# LPC408x_7x register map
File version: 0.7
CPU: CM4 r0p0, little endian, no MPU, no FPU, 3 interrupt priority bits
Registers are 32-bit, read-write, reset 0x0 unless marked. A register's access mark holds for its fields unless they carry their own. Offsets are from the block's base; [hi:lo] are bit positions; {n}, {i} and the like mark numbered series; 'fields as' and 'values as' point back to an identical list.

## EMC — External Memory Controller (EMC)
Base 0x2009C000
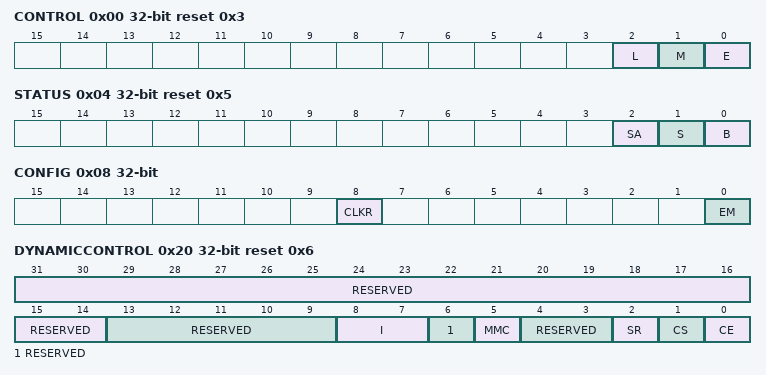
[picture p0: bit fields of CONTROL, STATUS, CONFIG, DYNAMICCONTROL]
0x00 CONTROL reset 0x3 — Controls operation of the memory controller.
  [2] L — Low-power mode. Indicates normal, or low-power mode:
    0=WARMRESET (Normal mode (warm reset value).); 1=LOWPOWER (Low-power mode. Entering low-power mode reduces memory controller power consumption. Dynamic memory is refreshed as necessary. The memory controller returns to normal functional mode by clearing the low-power mode bit (L), or by POR. This bit must only be modified when the EMC is in idle state.[1])
  [1] M — Address mirror. Indicates normal or reset memory map:
    0=NORMAL (Normal memory map.); 1=RESET (Reset memory map. Static memory EMC_CS1 is mirrored onto EMC_CS0 and EMC_DYCS0 (POR reset value).)
  [0] E — EMC Enable. Indicates if the EMC is enabled or disabled:
    0=DISABLED; 1=ENABLED (Enabled (POR and warm reset value).)
0x04 STATUS ro reset 0x5 — Provides EMC status information.
  [2] SA — Self-refresh acknowledge. This bit indicates the operating mode of the EMC.
    0=NORMAL (Normal mode); 1=SELFREFRESH (Self-refresh mode (POR reset value).)
  [1] S — Write buffer status.This bit enables the EMC to enter low-power mode or disabled mode cleanly.
    0=EMPTY (Write buffers empty (POR reset value)); 1=DATA (Write buffers contain data.)
  [0] B — Busy. This bit is used to ensure that the memory controller enters the low-power or disabled mode cleanly by determining if the memory controller is busy or not.
    0=IDLE (EMC is idle (warm reset value).); 1=BUSY (EMC is busy performing memory transactions, commands, auto-refresh cycles, or is in self-refresh mode (POR reset value).)
0x08 CONFIG — Configures operation of the memory controller
  [8] CLKR — CCLK: CLKOUT ratio. This bit must contain 0 for proper operation of the EMC.
    0=PORRESET (1:1(POR reset value)); 1=DONOTUSE (1:2 (this option is not available on the LPC178x/177x))
  [0] EM — Endian mode. On power-on reset, the value of the endian bit is 0. All data must be flushed in the EMC before switching between little-endian and big-endian modes.
    0=LITTLEENDIAN (Little-endian mode (POR reset value).); 1=BIGENDIAN (Big-endian mode.)
0x20 DYNAMICCONTROL reset 0x6 — Controls dynamic memory operation.
  [31:14] RESERVED — Reserved, user software should not write ones to reserved bits. The value read from a reserved bit is not defined.
  [13:9] RESERVED — Reserved, user software should not write ones to reserved bits. The value read from a reserved bit is not defined.
  [8:7] I — SDRAM initialization.
    0=NORMAL (Issue SDRAM NORMAL operation command (POR reset value).); 1=MODE (Issue SDRAM MODE command.); 2=PALL (Issue SDRAM PALL (precharge all) command.); 3=NOP (Issue SDRAM NOP (no operation) command))
  [6] RESERVED — Reserved, user software should not write ones to reserved bits. The value read from a reserved bit is not defined.
  [5] MMC — Memory clock control.
    0=CLKOUT_ENABLED_POR_ (CLKOUT enabled (POR reset value).); 1=CLKOUT_DISABLED (CLKOUT disabled.[3])
  [4:3] RESERVED — Reserved, user software should not write ones to reserved bits. The value read from a reserved bit is not defined.
  [2] SR — Self-refresh request, EMCSREFREQ. By writing 1 to this bit self-refresh can be entered under software control. Writing 0 to this bit returns the EMC to normal mode. The self-refresh acknowledge bit in the Status register must be polled to discover the current operating mode of the EMC.[2]
    0=NORMAL_MODE_; 1=ENTER_SELF_REFRESH_M (Enter self-refresh mode (POR reset value).)
  [1] CS — Dynamic memory clock control. When clock control is LOW the output clock CLKOUT is stopped when there are no SDRAM transactions. The clock is also stopped during self-refresh mode.
    0=STOP (CLKOUT stops when all SDRAMs are idle and during self-refresh mode.); 1=RUN (CLKOUT runs continuously (POR reset value).)
  [0] CE — Dynamic memory clock enable.
    0=POWERSAVE (Clock enable of idle devices are deasserted to save power (POR reset value).); 1=HIGH (All clock enables are driven HIGH continuously.[1])
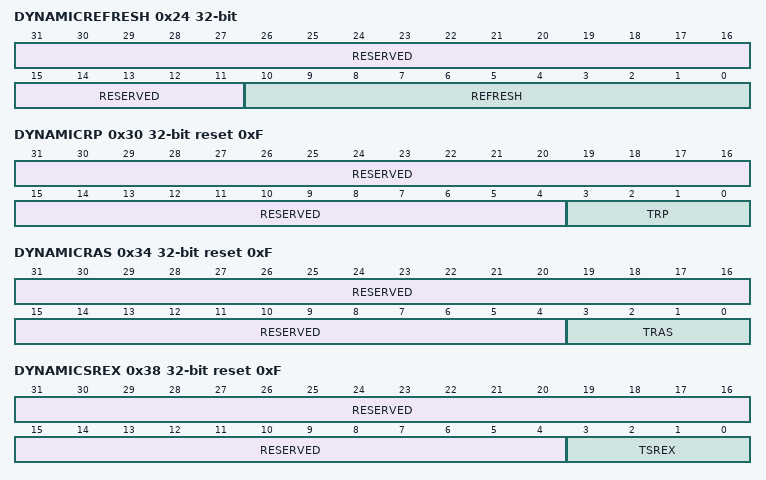
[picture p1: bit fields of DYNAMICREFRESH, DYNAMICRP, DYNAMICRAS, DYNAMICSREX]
0x24 DYNAMICREFRESH — Configures dynamic memory refresh.
  [31:11] RESERVED — Reserved, user software should not write ones to reserved bits. The value read from a reserved bit is not defined.
  [10:0] REFRESH — Refresh timer. Indicates the multiple of 16 CCLKs between SDRAM refresh cycles. 0x0 = Refresh disabled (POR reset value). 0x1 - 0x7FF = n x16 = 16n CCLKs between SDRAM refresh cycles. For example: 0x1 = 1 x 16 = 16 CCLKs between SDRAM refresh cycles. 0x8 = 8 x 16 = 128 CCLKs between SDRAM refresh cycles
0x28 DYNAMICREADCONFIG — Configures dynamic memory read strategy.
  [1:0] RD — Read data strategy
    0=CLOCK_OUT_DELAYED_ST (Clock out delayed strategy, using CLKOUT (command not delayed, clock out delayed). POR reset value.); 1=COMMAND_DELAYED_STRA (Command delayed strategy, using EMCCLKDELAY (command delayed, clock out not delayed).); 2=COMMAND_DELAYED_STRA (Command delayed strategy plus one clock cycle, using EMCCLKDELAY (command delayed, clock out not delayed).); 3=COMMAND_DELAYED_STRA (Command delayed strategy plus two clock cycles, using EMCCLKDELAY (command delayed, clock out not delayed).)
0x30 DYNAMICRP reset 0xF — Precharge command period.
  [31:4] RESERVED — Reserved, user software should not write ones to reserved bits. The value read from a reserved bit is not defined.
  [3:0] TRP — Precharge command period. 0x0 - 0xE = n + 1 clock cycles. The delay is in CCLK cycles. 0xF = 16 clock cycles (POR reset value).
0x34 DYNAMICRAS reset 0xF — Active to precharge command period.
  [31:4] RESERVED — Reserved, user software should not write ones to reserved bits. The value read from a reserved bit is not defined.
  [3:0] TRAS — Active to precharge command period. 0x0 - 0xE = n + 1 clock cycles. The delay is in CCLK cycles. 0xF = 16 clock cycles (POR reset value).
0x38 DYNAMICSREX reset 0xF — Self-refresh exit time.
  [31:4] RESERVED — Reserved, user software should not write ones to reserved bits. The value read from a reserved bit is not defined.
  [3:0] TSREX — Self-refresh exit time. 0x0 - 0xE = n + 1 clock cycles. The delay is in CCLK cycles. 0xF = 16 clock cycles (POR reset value).
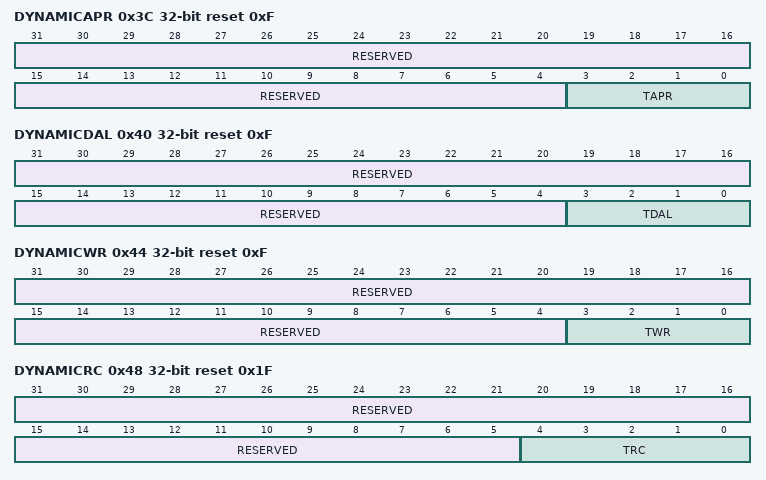
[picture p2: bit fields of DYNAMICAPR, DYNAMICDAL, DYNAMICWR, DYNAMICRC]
0x3C DYNAMICAPR reset 0xF — Last-data-out to active command time.
  [31:4] RESERVED — Reserved, user software should not write ones to reserved bits. The value read from a reserved bit is not defined.
  [3:0] TAPR — Last-data-out to active command time. 0x0 - 0xE = n + 1 clock cycles. The delay is in CCLK cycles. 0xF = 16 clock cycles (POR reset value).
0x40 DYNAMICDAL reset 0xF — Data-in to active command time.
  [31:4] RESERVED — Reserved, user software should not write ones to reserved bits. The value read from a reserved bit is not defined.
  [3:0] TDAL — Data-in to active command. 0x0 - 0xE = n clock cycles. The delay is in CCLK cycles. 0xF = 15 clock cycles (POR reset value).
0x44 DYNAMICWR reset 0xF — Write recovery time.
  [31:4] RESERVED — Reserved, user software should not write ones to reserved bits. The value read from a reserved bit is not defined.
  [3:0] TWR — Write recovery time. 0x0 - 0xE = n + 1 clock cycles. The delay is in CCLK cycles. 0xF = 16 clock cycles (POR reset value).
0x48 DYNAMICRC reset 0x1F — Selects the active to active command period.
  [31:5] RESERVED — Reserved, user software should not write ones to reserved bits. The value read from a reserved bit is not defined.
  [4:0] TRC — Active to active command period. 0x0 - 0x1E = n + 1 clock cycles. The delay is in CCLK cycles. 0x1F = 32 clock cycles (POR reset value).
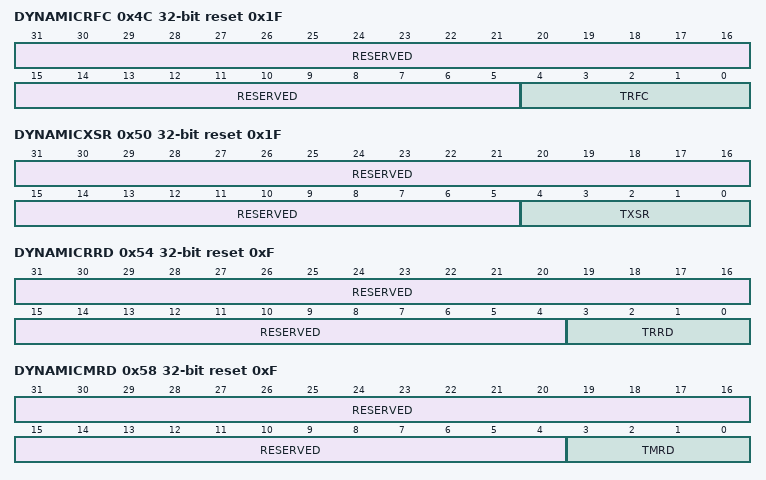
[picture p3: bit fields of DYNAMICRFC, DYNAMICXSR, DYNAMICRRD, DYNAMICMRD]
0x4C DYNAMICRFC reset 0x1F — Selects the auto-refresh period.
  [31:5] RESERVED — Reserved, user software should not write ones to reserved bits. The value read from a reserved bit is not defined.
  [4:0] TRFC — Auto-refresh period and auto-refresh to active command period. 0x0 - 0x1E = n + 1 clock cycles. The delay is in CCLK cycles. 0x1F = 32 clock cycles (POR reset value).
0x50 DYNAMICXSR reset 0x1F — Time for exit self-refresh to active command.
  [31:5] RESERVED — Reserved, user software should not write ones to reserved bits. The value read from a reserved bit is not defined.
  [4:0] TXSR — Exit self-refresh to active command time. 0x0 - 0x1E = n + 1 clock cycles. The delay is in CCLK cycles. 0x1F = 32 clock cycles (POR reset value).
0x54 DYNAMICRRD reset 0xF — Latency for active bank A to active bank B.
  [31:4] RESERVED — Reserved, user software should not write ones to reserved bits. The value read from a reserved bit is not defined.
  [3:0] TRRD — Active bank A to active bank B latency 0x0 - 0xE = n + 1 clock cycles. The delay is in CCLK cycles. 0xF = 16 clock cycles (POR reset value).
0x58 DYNAMICMRD reset 0xF — Time for load mode register to active command.
  [31:4] RESERVED — Reserved, user software should not write ones to reserved bits. The value read from a reserved bit is not defined.
  [3:0] TMRD — Load mode register to active command time. 0x0 - 0xE = n + 1 clock cycles. The delay is in CCLK cycles. 0xF = 16 clock cycles (POR reset value).
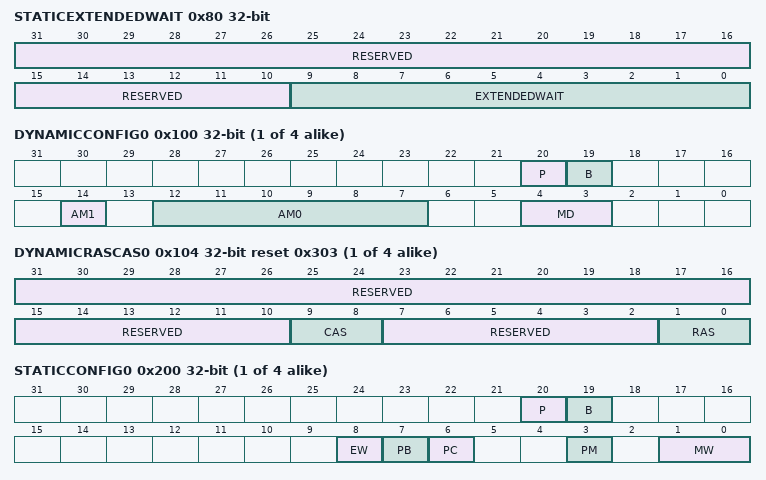
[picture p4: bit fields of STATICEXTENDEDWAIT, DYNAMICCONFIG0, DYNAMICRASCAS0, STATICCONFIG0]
0x80 STATICEXTENDEDWAIT — Time for long static memory read and write transfers.
  [31:10] RESERVED — Reserved, user software should not write ones to reserved bits. The value read from a reserved bit is not defined.
  [9:0] EXTENDEDWAIT — Extended wait time out. 16 clock cycles (POR reset value). The delay is in CCLK cycles. 0x0 = 16 clock cycles. 0x1 - 0x3FF = (n+1) x16 clock cycles.
{0x100+0x20*i} DYNAMICCONFIG{i} (i=0..3) — Configuration information for EMC_DYCS0.
  [20] P — Write protect.
    0=WRITES_NOT_PROTECTED (Writes not protected (POR reset value).); 1=WRITES_PROTECTED_
  [19] B — Buffer enable.
    0=BUFFER_DISABLED_FOR_ (Buffer disabled for accesses to this chip select (POR reset value).); 1=BUFFER_ENABLED_FOR_A (Buffer enabled for accesses to this chip select.[2])
  [14] AM1 — See Table 133. 0 = reset value.
  [12:7] AM0 — See Table 133. 000000 = reset value.[1]
  [4:3] MD — Memory device.
    0=SDRAM_POR_RESET_VAL (SDRAM (POR reset value).); 1=LOW_POWER_SDRAM_
{0x104+0x20*i} DYNAMICRASCAS{i} (i=0..3) reset 0x303 — RAS and CAS latencies for EMC_DYCS0.
  [31:10] RESERVED — Reserved, user software should not write ones to reserved bits. The value read from a reserved bit is not defined.
  [9:8] CAS — CAS latency.
    1=ONE_CCLK_CYCLE_; 2=TWO_CCLK_CYCLES_; 3=THREE_CCLK_CYCLES_P (Three CCLK cycles (POR reset value).)
  [7:2] RESERVED — Reserved, user software should not write ones to reserved bits. The value read from a reserved bit is not defined.
  [1:0] RAS — RAS latency (active to read/write delay).
    values as CAS
{0x200+0x20*i} STATICCONFIG{i} (i=0..3) — Configuration for EMC_CS0.
  [20] P — Write protect
    0=WRITES_NOT_PROTECTED (Writes not protected (POR reset value).); 1=WRITE_PROTECTED_
  [19] B — Buffer enable [2]
    0=BUFFER_DISABLED_POR (Buffer disabled (POR reset value).); 1=BUFFER_ENABLED_
  [8] EW — Extended wait (EW) uses the EMCStaticExtendedWait register to time both the read and write transfers rather than the EMCStaticWaitRd and EMCStaticWaitWr registers. This enables much longer transactions. [1]
    0=EXTENDED_WAIT_DISABL (Extended wait disabled (POR reset value).); 1=EXTENDED_WAIT_ENABLE (Extended wait enabled.)
  [7] PB — Byte lane state. The byte lane state bit, PB, enables different types of memory to be connected. For byte-wide static memories the BLS3:0 signal from the EMC is usually connected to WE (write enable). In this case for reads all the BLS3:0 bits must be HIGH. This means that the byte lane state (PB) bit must be LOW. 16 bit wide static memory devices usually have the BLS3:0 signals connected to the UBn and LBn (upper byte and lower byte) signals in the static memory. In this case a write to a particular byte must assert the appropriate UBn or LBn signal LOW. For reads, all the UB and LB signals must be asserted LOW so that the bus is driven. In this case the byte lane state (PB) bit must be HIGH.
    0=BLSHIGH (For reads all the bits in BLS3:0 are HIGH. For writes the respective active bits in BLS3:0 are LOW (POR reset value).); 1=BLSLOW (For reads the respective active bits in BLS3:0 are LOW. For writes the respective active bits in BLS3:0 are LOW.)
  [6] PC — Chip select polarity. The value of the chip select polarity on power-on reset is 0.
    0=ACTIVE_LOW_CHIP_SELE (Active LOW chip select.); 1=ACTIVE_HIGH_CHIP_SEL (Active HIGH chip select.)
  [3] PM — Page mode. In page mode the EMC can burst up to four external accesses. Therefore devices with asynchronous page mode burst four or higher devices are supported. Asynchronous page mode burst two devices are not supported and must be accessed normally.
    0=DISABLED_POR_RESET_ (Disabled (POR reset value).); 1=ASYNCHRONOUS_PAGE_MO (Asynchronous page mode enabled (page length four).)
  [1:0] MW — Memory width.
    0=8_BIT_POR_RESET_VAL (8 bit (POR reset value).); 1=16_BIT_; 2=32_BIT_
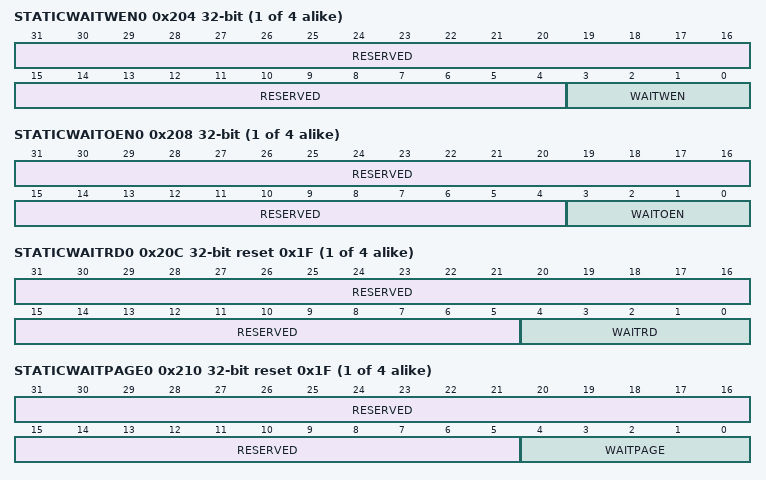
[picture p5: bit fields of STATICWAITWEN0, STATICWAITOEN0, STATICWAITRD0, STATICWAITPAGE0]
{0x204+0x20*i} STATICWAITWEN{i} (i=0..3) — Delay from EMC_CS0 to write enable.
  [31:4] RESERVED — Reserved, user software should not write ones to reserved bits. The value read from a reserved bit is not defined.
  [3:0] WAITWEN — Wait write enable. Delay from chip select assertion to write enable. 0x0 = One CCLK cycle delay between assertion of chip select and write enable (POR reset value). 0x1 - 0xF = (n + 1) CCLK cycle delay. The delay is (WAITWEN +1) x tCCLK.
{0x208+0x20*i} STATICWAITOEN{i} (i=0..3) — Delay from EMC_CS0 or address change, whichever is later, to output enable.
  [31:4] RESERVED — Reserved, user software should not write ones to reserved bits. The value read from a reserved bit is not defined.
  [3:0] WAITOEN — Wait output enable. Delay from chip select assertion to output enable. 0x0 = No delay (POR reset value). 0x1 - 0xF = n cycle delay. The delay is WAITOEN x tCCLK.
{0x20C+0x20*i} STATICWAITRD{i} (i=0..3) reset 0x1F — Delay from EMC_CS0 to a read access.
  [31:5] RESERVED — Reserved, user software should not write ones to reserved bits. The value read from a reserved bit is not defined.
  [4:0] WAITRD — Non-page mode read wait states or asynchronous page mode read first access wait state. Non-page mode read or asynchronous page mode read, first read only: 0x0 - 0x1E = (n + 1) CCLK cycles for read accesses. For non-sequential reads, the wait state time is (WAITRD + 1) x tCCLK. 0x1F = 32 CCLK cycles for read accesses (POR reset value).
{0x210+0x20*i} STATICWAITPAGE{i} (i=0..3) reset 0x1F — Delay for asynchronous page mode sequential accesses for EMC_CS0.
  [31:5] RESERVED — Reserved, user software should not write ones to reserved bits. The value read from a reserved bit is not defined.
  [4:0] WAITPAGE — Asynchronous page mode read after the first read wait states. Number of wait states for asynchronous page mode read accesses after the first read: 0x0 - 0x1E = (n+ 1) CCLK cycle read access time. For asynchronous page mode read for sequential reads, the wait state time for page mode accesses after the first read is (WAITPAGE + 1) x tCCLK. 0x1F = 32 CCLK cycle read access time (POR reset value).
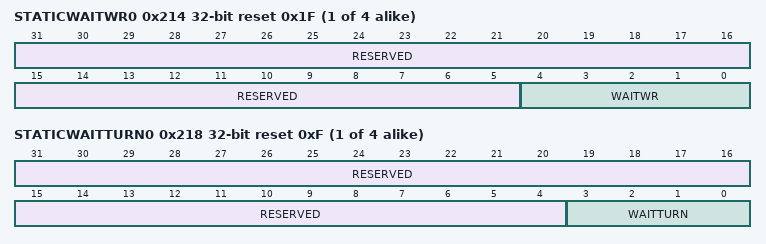
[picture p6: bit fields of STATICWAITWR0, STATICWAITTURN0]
{0x214+0x20*i} STATICWAITWR{i} (i=0..3) reset 0x1F — Delay from EMC_CS0 to a write access.
  [31:5] RESERVED — Reserved, user software should not write ones to reserved bits. The value read from a reserved bit is not defined.
  [4:0] WAITWR — Write wait states. SRAM wait state time for write accesses after the first read: 0x0 - 0x1E = (n + 2) CCLK cycle write access time. The wait state time for write accesses after the first read is WAITWR (n + 2) x tCCLK. 0x1F = 33 CCLK cycle write access time (POR reset value).
{0x218+0x20*i} STATICWAITTURN{i} (i=0..3) reset 0xF — Number of bus turnaround cycles EMC_CS0.
  [31:4] RESERVED — Reserved, user software should not write ones to reserved bits. The value read from a reserved bit is not defined.
  [3:0] WAITTURN — Bus turn-around cycles. 0x0 - 0xE = (n + 1) CCLK turn-around cycles. Bus turn-around time is (WAITTURN + 1) x tCCLK. 0xF = 16 CCLK turn-around cycles (POR reset value).
